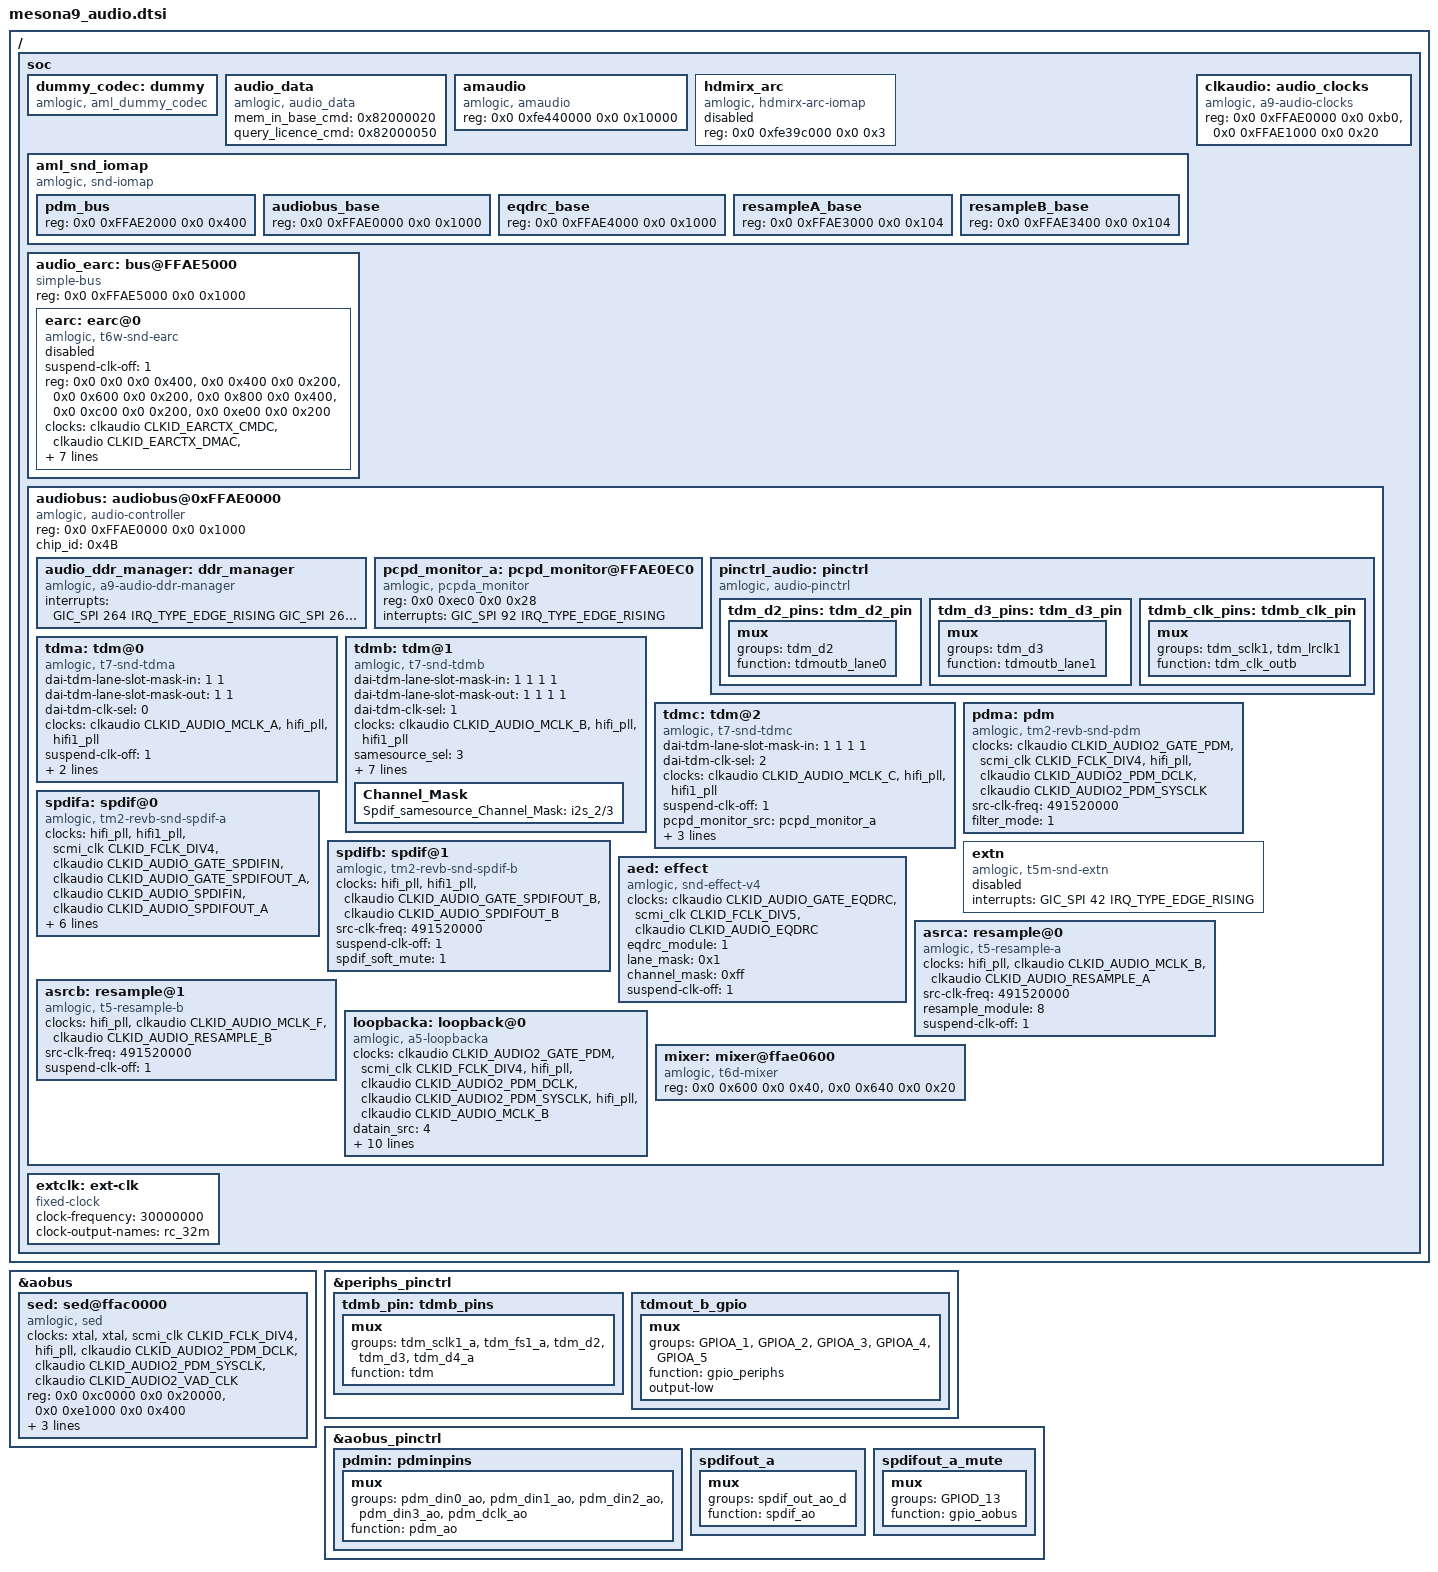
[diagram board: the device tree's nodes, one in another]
// SPDX-License-Identifier: (GPL-2.0+ OR MIT)
/*
 * Copyright (c) 2019 Amlogic, Inc. All rights reserved.
 */

#include <dt-bindings/clock/amlogic,a9-audio-clk.h>
/ {
	soc {
		dummy_codec:dummy{
			#sound-dai-cells = <0>;
			compatible = "amlogic, aml_dummy_codec";
			status = "okay";
		};

		audio_data: audio_data {
			compatible = "amlogic, audio_data";
			mem_in_base_cmd = <0x82000020>;
			query_licence_cmd = <0x82000050>;
			status = "okay";
		};

		amaudio: amaudio {
			compatible = "amlogic, amaudio";
			reg = <0x0 0xfe440000 0x0 0x10000>;
			reg-names = "otp_tee_base";
			status = "okay";
		};

		//hdmirx arc
		hdmirx_arc {
			compatible = "amlogic, hdmirx-arc-iomap";
			reg = <0x0 0xfe39c000 0x0 0x3>;
			#address-cells = <2>;
			#size-cells = <2>;
			ranges = <0x0 0x0 0x0 0xfe39c000 0x0 0x3>;
			reg-names = "hdmirx-arc";
			status = "disabled";
		};

		/* Sound iomap */
		aml_snd_iomap {
			compatible = "amlogic, snd-iomap";
			status = "okay";
			#address-cells=<2>;
			#size-cells=<2>;
			ranges;
			pdm_bus {
				reg = <0x0 0xFFAE2000 0x0 0x400>;
			};
			audiobus_base {
				reg = <0x0 0xFFAE0000 0x0 0x1000>;
			};
			eqdrc_base {
				reg = <0x0 0xFFAE4000 0x0 0x1000>;
			};
			resampleA_base {
				reg = <0x0 0xFFAE3000 0x0 0x104>;
			};
			resampleB_base {
				reg = <0x0 0xFFAE3400 0x0 0x104>;
			};
		};

		/* eARC */
		audio_earc: bus@FFAE5000 {
			compatible = "simple-bus";
			reg = <0x0 0xFFAE5000 0x0 0x1000>;
			#address-cells = <2>;
			#size-cells = <2>;
			ranges = <0x0 0x0 0x0 0xFFAE5000 0x0 0x1000>;
			earc: earc@0 {
				compatible = "amlogic, t6w-snd-earc";
				#sound-dai-cells = <0>;
				suspend-clk-off = <1>;
				reg =<0x0 0x0 0x0 0x400>,
					<0x0 0x400 0x0 0x200>,
					<0x0 0x600 0x0 0x200>,
					<0x0 0x800 0x0 0x400>,
					<0x0 0xc00 0x0 0x200>,
					<0x0 0xe00 0x0 0x200>;
				reg-names = "tx_cmdc",
						"tx_dmac",
						"tx_top",
						"rx_cmdc",
						"rx_dmac",
						"rx_top";

				clocks = < &clkaudio CLKID_EARCTX_CMDC
						&clkaudio CLKID_EARCTX_DMAC
						&scmi_clk CLKID_FCLK_DIV4
						&hifi_pll
						&hifi1_pll
						&clkaudio CLKID_EARCRX_CMDC
						&clkaudio CLKID_EARCRX_DMAC
						&scmi_clk CLKID_FCLK_DIV4
						&scmi_clk CLKID_FCLK_DIV4
						>;
				clock-names =
						"tx_cmdc",
						"tx_dmac",
						"tx_cmdc_srcpll",
						"tx_dmac_srcpll",
						"clk_src_cd",
						"rx_cmdc",
						"rx_dmac",
						"rx_cmdc_srcpll",
						"rx_dmac_srcpll";
				interrupts = <
					GIC_SPI 280 IRQ_TYPE_LEVEL_HIGH
					GIC_SPI 281 IRQ_TYPE_LEVEL_HIGH>;
				interrupt-names = "earc_rx", "earc_tx";
				status = "disabled";
			};
		};
		clkaudio: audio_clocks {
			compatible = "amlogic, a9-audio-clocks";
			#clock-cells = <1>;
			reg = <0x0 0xFFAE0000 0x0 0xb0>, <0x0 0xFFAE1000 0x0 0x20>;
			reg-names = "audio_bus", "audio_vad_top";
			//power-domains = <&pwrdm PDID_C4_AUDIO_TOP>;
			status = "okay";
		};
		audiobus: audiobus@0xFFAE0000 {
			compatible = "amlogic, audio-controller", "simple-bus";
			reg = <0x0 0xFFAE0000 0x0 0x1000>;
			reg-names = "audio_bus";
			#address-cells = <2>;
			#size-cells = <2>;
			ranges = <0x0 0x0 0x0 0xFFAE0000 0x0 0x1000>;
			chip_id = <0x4B>;
			status = "okay";
			audio_ddr_manager: ddr_manager {
				compatible =
					"amlogic, a9-audio-ddr-manager";
				interrupts = <
					GIC_SPI 264 IRQ_TYPE_EDGE_RISING
					GIC_SPI 265 IRQ_TYPE_EDGE_RISING
					GIC_SPI 266 IRQ_TYPE_EDGE_RISING
					GIC_SPI 277 IRQ_TYPE_EDGE_RISING
					GIC_SPI 268 IRQ_TYPE_EDGE_RISING
					GIC_SPI 269 IRQ_TYPE_EDGE_RISING
					GIC_SPI 270 IRQ_TYPE_EDGE_RISING
					GIC_SPI 278 IRQ_TYPE_EDGE_RISING
				>;
				interrupt-names =
					"toddr_a", "toddr_b", "toddr_c",
					"toddr_d",
					"frddr_a", "frddr_b", "frddr_c",
					"frddr_d";
			};

			pcpd_monitor_a: pcpd_monitor@FFAE0EC0 {
				compatible = "amlogic, pcpda_monitor";
				/*regbase:0xFFAE0EC0 + 0x3b0 << 2*/
				/*size 0x28 byte*/
				reg =<0x0 0xec0 0x0 0x28>;
				reg-names = "pcpd_reg";
				interrupts = <GIC_SPI 92
					IRQ_TYPE_EDGE_RISING>;
				interrupt-names = "irq_pcpd";
				status = "okay";
			};

			pinctrl_audio: pinctrl {
				compatible = "amlogic, audio-pinctrl";
				status = "okay";
			};
		};/* end of audiobus*/
		extclk: ext-clk {
			compatible = "fixed-clock";
			clock-frequency = <30000000>;
			clock-output-names = "rc_32m";
			#clock-cells = <0>;
		};
	};/*end soc*/
};

&audiobus {
	tdma:tdm@0 {
		compatible = "amlogic, t7-snd-tdma";
		#sound-dai-cells = <0>;

		dai-tdm-lane-slot-mask-in = <1 1>;
		dai-tdm-lane-slot-mask-out = <1 1>;
		dai-tdm-clk-sel = <0>;
		clocks = <&clkaudio CLKID_AUDIO_MCLK_A
				&hifi_pll
				&hifi1_pll>;
		clock-names = "mclk", "clk_srcpll", "clk_src_cd";
		suspend-clk-off = <1>;
		/* enable control gain */
		ctrl_gain = <1>;
		src-clk-freq = <491520000>;
		status = "okay";
	};

	tdmb:tdm@1 {
		compatible = "amlogic, t7-snd-tdmb";
		#sound-dai-cells = <0>;

		dai-tdm-lane-slot-mask-in = <1 1 1 1>;
		dai-tdm-lane-slot-mask-out = <1 1 1 1>;
		dai-tdm-clk-sel = <1>;

		clocks = <&clkaudio CLKID_AUDIO_MCLK_B
				&hifi_pll
				&hifi1_pll>;
		clock-names = "mclk", "clk_srcpll", "clk_src_cd";
		/*
		 * 0: tdmout_a;
		 * 1: tdmout_b;
		 * 2: tdmout_c;
		 * 3: spdifout;
		 * 4: spdifout_b;
		 */
		samesource_sel = <3>;
		/* In for ACODEC_ADC */
		/* tdmin-src-name = "acodec_adc"; */
		tdmin-src-name = "hdmirx";
		/*enable default mclk(12.288M), before extern codec start*/
		start_clk_enable = <1>;

		/*tdm clk tuning enable*/
		clk_tuning_enable = <1>;

		/* enable control gain */
		ctrl_gain = <1>;
		suspend-clk-off = <1>;
		mixer_enable = <1>;
		status = "okay";
		src-clk-freq = <491520000>;
		/* !!!For --TV platform-- ONLY */
		Channel_Mask {
			/*i2s has 4 pins, 8channel, mux output*/
			Spdif_samesource_Channel_Mask = "i2s_2/3";
		};
	};

	tdmc:tdm@2 {
		compatible = "amlogic, t7-snd-tdmc";
		#sound-dai-cells = <0>;

		dai-tdm-lane-slot-mask-in = <1 1 1 1>;
		dai-tdm-clk-sel = <2>;

		clocks = <&clkaudio CLKID_AUDIO_MCLK_C
				&hifi_pll
				&hifi1_pll>;
		clock-names = "mclk", "clk_srcpll", "clk_src_cd";
		suspend-clk-off = <1>;

		/* pcpd_monitor*/
		pcpd_monitor_src = <&pcpd_monitor_a>;
		src-clk-freq = <491520000>;
		/* enable control gain */
		tdmin-src-name = "hdmirx";
		ctrl_gain = <1>;
		status = "okay";
	};

	pdma: pdm {
		compatible = "amlogic, tm2-revb-snd-pdm";
		#sound-dai-cells = <0>;
		clocks = <&clkaudio CLKID_AUDIO2_GATE_PDM
			&scmi_clk CLKID_FCLK_DIV4
			&hifi_pll
			&clkaudio CLKID_AUDIO2_PDM_DCLK
			&clkaudio CLKID_AUDIO2_PDM_SYSCLK>;
		clock-names = "gate",
			"sysclk_srcpll",
			"dclk_srcpll",
			"pdm_dclk",
			"pdm_sysclk";
		//pinctrl-names = "pdm_pins";
		//pinctrl-0 = <&pdmin>;
		src-clk-freq = <491520000>;
		/* mode 0~4, defalut:1 */
		filter_mode = <1>;
		status = "okay";
	};

	spdifa:spdif@0 {
		compatible = "amlogic, tm2-revb-snd-spdif-a";
		#sound-dai-cells = <0>;

		clocks = <&hifi_pll
				&hifi1_pll
				&scmi_clk CLKID_FCLK_DIV4
				&clkaudio CLKID_AUDIO_GATE_SPDIFIN
				&clkaudio CLKID_AUDIO_GATE_SPDIFOUT_A
				&clkaudio CLKID_AUDIO_SPDIFIN
				&clkaudio CLKID_AUDIO_SPDIFOUT_A>;
		clock-names = "sysclk", "clk_src_cd", "fixed_clk", "gate_spdifin",
				"gate_spdifout", "clk_spdifin", "clk_spdifout";

		interrupts =
				<GIC_SPI 267 IRQ_TYPE_EDGE_RISING>;
		interrupt-names = "irq_spdifin";
		/*
		 * 0: tdmout_a;
		 * 1: tdmout_b;
		 * 2: tdmout_c;
		 * 3: spdifout;
		 * 4: spdifout_b;
		 * 5: earc;
		 */
		spdif_soft_mute = <1>;
		samesource_sel = <5>;
		src-clk-freq = <491520000>;
		/*spdif clk tuning enable*/
		clk_tuning_enable = <1>;
		suspend-clk-off = <1>;
		status = "okay";
	};

	spdifb:spdif@1 {
		compatible = "amlogic, tm2-revb-snd-spdif-b";
		#sound-dai-cells = <0>;

		clocks = <&hifi_pll /*CLKID_HIFI_PLL*/
				&hifi1_pll
				&clkaudio CLKID_AUDIO_GATE_SPDIFOUT_B
				&clkaudio CLKID_AUDIO_SPDIFOUT_B>;
		clock-names = "sysclk", "clk_src_cd",
				"gate_spdifout", "clk_spdifout";
		src-clk-freq = <491520000>;
		suspend-clk-off = <1>;
		spdif_soft_mute = <1>;
		status = "okay";
	};

	extn:extn {
		compatible = "amlogic, t5m-snd-extn";
		#sound-dai-cells = <0>;

		interrupts =
				<GIC_SPI 42 IRQ_TYPE_EDGE_RISING>;
		interrupt-names = "irq_frhdmirx";

		status = "disabled";
	};

	aed:effect {
		compatible = "amlogic, snd-effect-v4";
		#sound-dai-cells = <0>;

		clocks = <&clkaudio CLKID_AUDIO_GATE_EQDRC
			&scmi_clk CLKID_FCLK_DIV5
			&clkaudio CLKID_AUDIO_EQDRC>;
		clock-names = "gate", "srcpll", "eqdrc";

		/*
		 * 0:tdmout_a
		 * 1:tdmout_b
		 * 2:tdmout_c
		 * 3:spdifout
		 * 4:spdifout_b
		 */
		eqdrc_module = <1>;
		/* max 0xf, each bit for one lane, usually one lane */
		lane_mask = <0x1>;
		/* max 0xff, each bit for one channel */
		channel_mask = <0xff>;
		suspend-clk-off = <1>;
		status = "okay";
	};

	asrca: resample@0 {
		compatible = "amlogic, t5-resample-a";
		clocks = <&hifi_pll
			&clkaudio CLKID_AUDIO_MCLK_B
			&clkaudio CLKID_AUDIO_RESAMPLE_A>;
		clock-names = "resample_pll", "resample_src", "resample_clk";

		/*same with toddr_src
		 *	TDMIN_A,    0
		 *	TDMIN_B,    1
		 *	TDMIN_C,    2
		 *	SPDIFIN,    3
		 *	PDMIN,      4
		 *	FRATV,      5
		 *	TDMIN_LB,   6
		 *	LOOPBACK_A, 7
		 *	FRHDMIRX,   8
		 *	LOOPBACK_B, 9
		 *	SPDIFIN_LB, 10
		 *	EARC_RX,    11
		 */
		src-clk-freq = <491520000>;
		resample_module = <8>;
		suspend-clk-off = <1>;
		status = "okay";
	};

	asrcb: resample@1 {
		compatible = "amlogic, t5-resample-b";
		clocks = <&hifi_pll
			&clkaudio CLKID_AUDIO_MCLK_F
			&clkaudio CLKID_AUDIO_RESAMPLE_B>;
		clock-names = "resample_pll", "resample_src", "resample_clk";
		src-clk-freq = <491520000>;
		/*this resample is only used for loopback_A.*/
		suspend-clk-off = <1>;
		status = "okay";
	};

	loopbacka:loopback@0 {
		compatible = "amlogic, a5-loopbacka";
		#sound-dai-cells = <0>;

		clocks = <&clkaudio CLKID_AUDIO2_GATE_PDM
			&scmi_clk CLKID_FCLK_DIV4
			&hifi_pll
			&clkaudio CLKID_AUDIO2_PDM_DCLK
			&clkaudio CLKID_AUDIO2_PDM_SYSCLK
			&hifi_pll
			&clkaudio CLKID_AUDIO_MCLK_B>;
		clock-names = "pdm_gate",
			"pdm_sysclk_srcpll",
			"pdm_dclk_srcpll",
			"pdm_dclk",
			"pdm_sysclk",
			"tdminlb_mpll",
			"tdminlb_mclk";

		/* datain src
		 * 0: tdmin_a;
		 * 1: tdmin_b;
		 * 2: tdmin_c;
		 * 3: spdifin;
		 * 4: pdmin;
		 */
		datain_src = <4>;
		datain_chnum = <2>;
		datain_chmask = <0x3>;
		/* config which data pin for loopback */
		datain-lane-mask-in = <1 1 0 0>;

		/* calc mclk for datalb */
		mclk-fs = <256>;
		/* tdmin_lb src
		 * 0: tdmoutA
		 * 1: tdmoutB
		 * 2: tdmoutC
		 * 3: PAD_TDMINA_DIN*, refer to core pinmux
		 * 4: PAD_TDMINB_DIN*, refer to core pinmux
		 * 5: PAD_TDMINC_DIN*, refer to core pinmux
		 * 6: PAD_TDMINA_D*, oe, refer to core pinmux
		 * 7: PAD_TDMINB_D*, oe, refer to core pinmux
		 */
		/* if tdmin_lb >= 3, use external loopback */
		datalb_src = <1>;
		datalb_chnum = <2>;
		datalb_chmask = <0x3>;
		/* config which data pin as loopback */
		datalb-lane-mask-in = <1 0 0 0>;

		src-clk-freq = <491520000>;
		mic-src = <&pdma>;
		status = "okay";
	};

	mixer: mixer@ffae0600 {
		compatible = "amlogic, t6d-mixer";
		#sound-dai-cells = <0>;
		reg = <0x0 0x600 0x0 0x40>,
			<0x0 0x640 0x0 0x20>;
		reg-names = "coef_reg", "mixer_reg";
		status = "okay";
	};
}; /* end of audiobus */

&aobus {
	sed: sed@ffac0000 {
		compatible = "amlogic, sed";
		#sound-dai-cells = <0>;
		clocks = <
			&xtal
			&xtal
			&scmi_clk CLKID_FCLK_DIV4
			&hifi_pll
			&clkaudio CLKID_AUDIO2_PDM_DCLK
			&clkaudio CLKID_AUDIO2_PDM_SYSCLK
			&clkaudio CLKID_AUDIO2_VAD_CLK>;
		clock-names =
			"rc_pll",
			"sed_clk_pll",
			"sysclk_srcpll",
			"dclk_srcpll",
			"pdm_dclk",
			"pdm_sysclk",
			"sed_clk";
		reg = <0x0 0xc0000 0x0 0x20000>,
			<0x0 0xe1000 0x0 0x400>;
		reg-names = "sed_reg", "audio_top_reg";
		interrupts = <
					GIC_SPI 405 IRQ_TYPE_EDGE_RISING
					GIC_SPI 406 IRQ_TYPE_EDGE_RISING
					>;
		interrupt-names ="irq_wakeup", "sed_err_irq";
		mic-src = <&pdma>;
	};
};

&periphs_pinctrl {
	tdmb_pin: tdmb_pins {
		mux { /* GPIOA_1 GPIOA_2  GPIOA_3  GPIOA_4 GPIOA_5*/
			groups = "tdm_sclk1_a",
				"tdm_fs1_a",
				"tdm_d2",
				"tdm_d3",
				"tdm_d4_a";
			function = "tdm";
		};
	};

	tdmout_b_gpio: tdmout_b_gpio {
		mux { /* GPIOA_1, GPIOA_2, GPIOA_3  GPIOA_5*/
			groups ="GPIOA_1",
				"GPIOA_2",
				"GPIOA_3",
				"GPIOA_4",
				"GPIOA_5";
			function = "gpio_periphs";
			output-low;
		};
	};
};

&aobus_pinctrl {
	pdmin: pdminpins {
		mux { /* GPIOAO_6  GPIOAO_10*/
			groups = "pdm_din0_ao",
				"pdm_din1_ao",
				"pdm_din2_ao",
				"pdm_din3_ao",
				"pdm_dclk_ao";
			function = "pdm_ao";
		};
	};
	spdifout_a: spdifout_a {
		mux { /* GPIOD_13 */
			groups = "spdif_out_ao_d";
			function = "spdif_ao";
		};
	};

	spdifout_a_mute: spdifout_a_mute {
		mux { /* GPIOD_13 */
			groups = "GPIOD_13";
			function = "gpio_aobus";
		};
	};
};

&pinctrl_audio {
	tdm_d2_pins: tdm_d2_pin {
		mux {
			groups = "tdm_d2";
			function = "tdmoutb_lane0";
		};
	};

	tdm_d3_pins: tdm_d3_pin {
		mux {
			groups = "tdm_d3";
			function = "tdmoutb_lane1";
		};
	};

	tdmb_clk_pins: tdmb_clk_pin {
		mux {
			groups = "tdm_sclk1", "tdm_lrclk1";
			function = "tdm_clk_outb";
		};
	};
};

